# CC1350F128 register map
File version: 1.0
CPU: CM3 1.0, other endian, MPU, FPU, 3 interrupt priority bits
Registers are 32-bit, read-write, reset 0x0 unless marked. A register's access mark holds for its fields unless they carry their own. Offsets are from the block's base; [hi:lo] are bit positions; {n}, {i} and the like mark numbered series; 'fields as' and 'values as' point back to an identical list.

## PRCM — Power, Reset and Clock Management
Base 0x40082000
0x00 INFRCLKDIVR — Infrastructure Clock Division Factor For Run Mode
  [1:0] RATIO — [1:0] Division rate for clocks driving modules in the MCU_AON domain when system CPU is in run mode. Division ratio affects both infrastructure clock and perbusull clock.
    3=DIV32 (Divide by 32); 2=DIV8 (Divide by 8); 1=DIV2 (Divide by 2); 0=DIV1 (Divide by 1)
0x04 INFRCLKDIVS — Infrastructure Clock Division Factor For Sleep Mode
  [1:0] RATIO — [1:0] Division rate for clocks driving modules in the MCU_AON domain when system CPU is in sleep mode. Division ratio affects both infrastructure clock and perbusull clock.
    values as INFRCLKDIVR.RATIO
0x08 INFRCLKDIVDS — Infrastructure Clock Division Factor For DeepSleep Mode
  [1:0] RATIO — [1:0] Division rate for clocks driving modules in the MCU_AON domain when system CPU is in seepsleep mode. Division ratio affects both infrastructure clock and perbusull clock.
    values as INFRCLKDIVR.RATIO
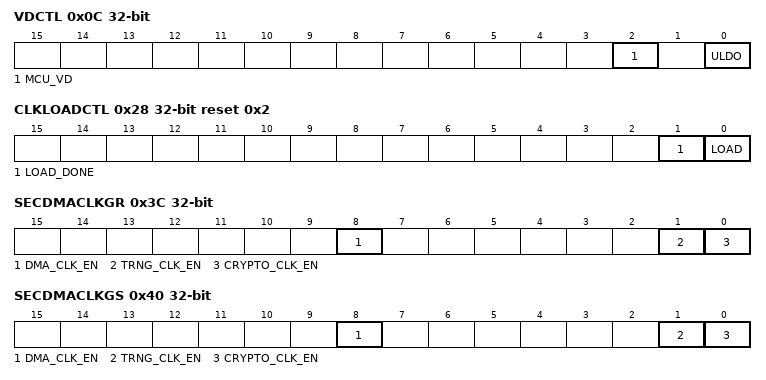
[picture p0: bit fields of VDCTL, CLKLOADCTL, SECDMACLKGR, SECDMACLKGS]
0x0C VDCTL — MCU Voltage Domain Control
  [2] MCU_VD — [2:2] Request WUC to power down the MCU voltage domain 0: No request 1: Assert request when possible. An asserted power down request will result in a boot of the MCU system when powered up again. The bit will have no effect before the following requirements are met: 1. PDCTL1.CPU_ON = 0 2. PDCTL1.VIMS_MODE = 0 3. SECDMACLKGDS.DMA_CLK_EN = 0 (Note: Setting must be loaded with CLKLOADCTL.LOAD) 4. SECDMACLKGDS.CRYPTO_CLK_EN = 0 (Note: Setting must be loaded with CLKLOADCTL.LOAD) 5. RFC do no request access to BUS 6. System CPU in deepsleep
  [0] ULDO — [0:0] Request WUC to switch to uLDO. 0: No request 1: Assert request when possible The bit will have no effect before the following requirements are met: 1. PDCTL1.CPU_ON = 0 2. PDCTL1.VIMS_MODE = 0 3. SECDMACLKGDS.DMA_CLK_EN = 0 (Note: Setting must be loaded with CLKLOADCTL.LOAD) 4. SECDMACLKGDS.CRYPTO_CLK_EN = 0 (Note: Setting must be loaded with CLKLOADCTL.LOAD) 5. RFC do no request access to BUS 6. System CPU in deepsleep
0x28 CLKLOADCTL reset 0x2 — Load PRCM Settings To CLKCTRL Power Domain
  [1] LOAD_DONE ro — [1:1] Status of LOAD. Will be cleared to 0 when any of the registers requiring a LOAD is written to, and be set to 1 when a LOAD is done. Note that writing no change to a register will result in the LOAD_DONE being cleared. 0 : One or more registers have been write accessed after last LOAD 1 : No registers are write accessed after last LOAD
  [0] LOAD wo — [0:0] 0: No action 1: Load settings to CLKCTRL. Bit is HW cleared. Multiple changes to settings may be done before LOAD is written once so all changes takes place at the same time. LOAD can also be done after single setting updates. Registers that needs to be followed by LOAD before settings being applied are: - RFCCLKG - VIMSCLKG - SECDMACLKGR - SECDMACLKGS - SECDMACLKGDS - GPIOCLKGR - GPIOCLKGS - GPIOCLKGDS - GPTCLKGR - GPTCLKGS - GPTCLKGDS - GPTCLKDIV - I2CCLKGR - I2CCLKGS - I2CCLKGDS - SSICLKGR - SSICLKGS - SSICLKGDS - UARTCLKGR - UARTCLKGS - UARTCLKGDS - I2SCLKGR - I2SCLKGS - I2SCLKGDS - I2SBCLKSEL - I2SCLKCTL - I2SMCLKDIV - I2SBCLKDIV - I2SWCLKDIV
0x2C RFCCLKG reset 0x1 — RFC Clock Gate
  [0] CLK_EN — [0:0] 0: Disable clock 1: Enable clock if RFC power domain is on For changes to take effect, CLKLOADCTL.LOAD needs to be written
0x30 VIMSCLKG reset 0x3 — VIMS Clock Gate
  [1:0] CLK_EN — [1:0] 00: Disable clock 01: Disable clock when system CPU is in DeepSleep 11: Enable clock For changes to take effect, CLKLOADCTL.LOAD needs to be written
0x3C SECDMACLKGR — TRNG, CRYPTO And UDMA Clock Gate For Run Mode
  [8] DMA_CLK_EN — [8:8] 0: Disable clock 1: Enable clock For changes to take effect, CLKLOADCTL.LOAD needs to be written
  [1] TRNG_CLK_EN — [1:1] 0: Disable clock 1: Enable clock For changes to take effect, CLKLOADCTL.LOAD needs to be written
  [0] CRYPTO_CLK_EN — [0:0] 0: Disable clock 1: Enable clock For changes to take effect, CLKLOADCTL.LOAD needs to be written
0x40 SECDMACLKGS — TRNG, CRYPTO And UDMA Clock Gate For Sleep Mode
  fields as SECDMACLKGR
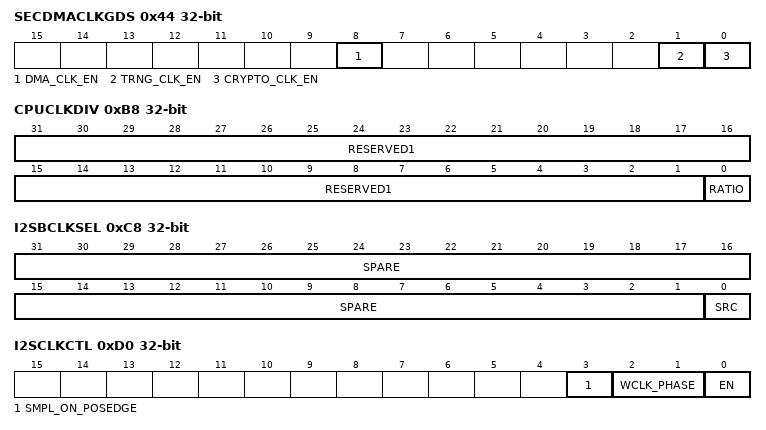
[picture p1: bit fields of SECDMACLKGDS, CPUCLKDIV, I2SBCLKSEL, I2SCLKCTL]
0x44 SECDMACLKGDS — TRNG, CRYPTO And UDMA Clock Gate For Deep Sleep Mode
  fields as SECDMACLKGR
0x48 GPIOCLKGR — GPIO Clock Gate For Run Mode
  [0] CLK_EN — [0:0] 0: Disable clock 1: Enable clock For changes to take effect, CLKLOADCTL.LOAD needs to be written
0x4C GPIOCLKGS — GPIO Clock Gate For Sleep Mode
  fields as GPIOCLKGR
0x50 GPIOCLKGDS — GPIO Clock Gate For Deep Sleep Mode
  fields as GPIOCLKGR
0x54 GPTCLKGR — GPT Clock Gate For Run Mode
  [3:0] CLK_EN — [3:0] Each bit below has the following meaning: 0: Disable clock 1: Enable clock ENUMs can be combined For changes to take effect, CLKLOADCTL.LOAD needs to be written
    8=GPT3 (Enable clock for GPT3); 4=GPT2 (Enable clock for GPT2); 2=GPT1 (Enable clock for GPT1); 1=GPT0 (Enable clock for GPT0)
0x58 GPTCLKGS — GPT Clock Gate For Sleep Mode
  fields as GPTCLKGR
0x5C GPTCLKGDS — GPT Clock Gate For Deep Sleep Mode
  fields as GPTCLKGR
0x60 I2CCLKGR — I2C Clock Gate For Run Mode
  fields as GPIOCLKGR
0x64 I2CCLKGS — I2C Clock Gate For Sleep Mode
  fields as GPIOCLKGR
0x68 I2CCLKGDS — I2C Clock Gate For Deep Sleep Mode
  fields as GPIOCLKGR
0x6C UARTCLKGR — UART Clock Gate For Run Mode
  fields as GPIOCLKGR
0x70 UARTCLKGS — UART Clock Gate For Sleep Mode
  fields as GPIOCLKGR
0x74 UARTCLKGDS — UART Clock Gate For Deep Sleep Mode
  fields as GPIOCLKGR
0x78 SSICLKGR — SSI Clock Gate For Run Mode
  [1:0] CLK_EN — [1:0] 0: Disable clock 1: Enable clock For changes to take effect, CLKLOADCTL.LOAD needs to be written
    2=SSI1 (Enable clock for SSI1); 1=SSI0 (Enable clock for SSI0)
0x7C SSICLKGS — SSI Clock Gate For Sleep Mode
  fields as SSICLKGR
0x80 SSICLKGDS — SSI Clock Gate For Deep Sleep Mode
  fields as SSICLKGR
0x84 I2SCLKGR — I2S Clock Gate For Run Mode
  fields as GPIOCLKGR
0x88 I2SCLKGS — I2S Clock Gate For Sleep Mode
  fields as GPIOCLKGR
0x8C I2SCLKGDS — I2S Clock Gate For Deep Sleep Mode
  fields as GPIOCLKGR
0xB8 CPUCLKDIV — Internal. Only to be used through TI provided API.
  [31:1] RESERVED1 ro — [31:1] Internal. Only to be used through TI provided API.
  [0] RATIO — [0:0] Internal. Only to be used through TI provided API.
    1=DIV2 (Internal. Only to be used through TI provided API.); 0=DIV1 (Internal. Only to be used through TI provided API.)
0xC0 PERBUSDMACLKDIV — Internal. Only to be used through TI provided API.
  [31:0] SPARE — [31:0] Internal. Only to be used through TI provided API.
0xC8 I2SBCLKSEL — I2S Clock Control
  [31:1] SPARE — [31:1] Software should not rely on the value of a reserved. Writing any other value than the reset value may result in undefined behavior.
  [0] SRC — [0:0] BCLK source selector 0: Use external BCLK 1: Use internally generated clock For changes to take effect, CLKLOADCTL.LOAD needs to be written
0xCC GPTCLKDIV — GPT Scalar
  [3:0] RATIO — [3:0] Scalar used for GPTs. The division rate will be constant and ungated for Run / Sleep / DeepSleep mode. For changes to take effect, CLKLOADCTL.LOAD needs to be written Other values are not supported.
    8=DIV256 (Divide by 256); 7=DIV128 (Divide by 128); 6=DIV64 (Divide by 64); 5=DIV32 (Divide by 32); 4=DIV16 (Divide by 16); 3=DIV8 (Divide by 8); 2=DIV4 (Divide by 4); 1=DIV2 (Divide by 2); 0=DIV1 (Divide by 1)
0xD0 I2SCLKCTL — I2S Clock Control
  [3] SMPL_ON_POSEDGE — [3:3] On the I2S serial interface, data and WCLK is sampled and clocked out on opposite edges of BCLK. 0 - data and WCLK are sampled on the negative edge and clocked out on the positive edge. 1 - data and WCLK are sampled on the positive edge and clocked out on the negative edge. For changes to take effect, CLKLOADCTL.LOAD needs to be written
  [2:1] WCLK_PHASE — [2:1] Decides how the WCLK division ratio is calculated and used to generate different duty cycles (See I2SWCLKDIV.WDIV). 0: Single phase 1: Dual phase 2: User Defined 3: Reserved/Undefined For changes to take effect, CLKLOADCTL.LOAD needs to be written
  [0] EN — [0:0] 0: MCLK, BCLK and WCLK will be static low 1: Enables the generation of MCLK, BCLK and WCLK For changes to take effect, CLKLOADCTL.LOAD needs to be written
0xD4 I2SMCLKDIV — MCLK Division Ratio
  [9:0] MDIV — [9:0] An unsigned factor of the division ratio used to generate MCLK [2-1024]: MCLK = MCUCLK/MDIV[Hz] MCUCLK is 48MHz in normal mode. For powerdown mode the frequency is defined by AON_WUC:MCUCLK.PWR_DWN_SRC A value of 0 is interpreted as 1024. A value of 1 is invalid. If MDIV is odd the low phase of the clock is one MCUCLK period longer than the high phase. For changes to take effect, CLKLOADCTL.LOAD needs to be written
0xD8 I2SBCLKDIV — BCLK Division Ratio
  [9:0] BDIV — [9:0] An unsigned factor of the division ratio used to generate I2S BCLK [2-1024]: BCLK = MCUCLK/BDIV[Hz] MCUCLK is 48MHz in normal mode. For powerdown mode the frequency is defined by AON_WUC:MCUCLK.PWR_DWN_SRC A value of 0 is interpreted as 1024. A value of 1 is invalid. If BDIV is odd and I2SCLKCTL.SMPL_ON_POSEDGE = 0, the low phase of the clock is one MCUCLK period longer than the high phase. If BDIV is odd and I2SCLKCTL.SMPL_ON_POSEDGE = 1 , the high phase of the clock is one MCUCLK period longer than the low phase. For changes to take effect, CLKLOADCTL.LOAD needs to be written
0xDC I2SWCLKDIV — WCLK Division Ratio
  [15:0] WDIV — [15:0] If I2SCLKCTL.WCLK_PHASE = 0, Single phase. WCLK is high one BCLK period and low WDIV[9:0] (unsigned, [1-1023]) BCLK periods. WCLK = MCUCLK / BDIV*(WDIV[9:0] + 1) [Hz] MCUCLK is 48MHz in normal mode. For powerdown mode the frequency is defined by AON_WUC:MCUCLK.PWR_DWN_SRC If I2SCLKCTL.WCLK_PHASE = 1, Dual phase. Each phase on WCLK (50% duty cycle) is WDIV[9:0] (unsigned, [1-1023]) BCLK periods. WCLK = MCUCLK / BDIV*(2*WDIV[9:0]) [Hz] If I2SCLKCTL.WCLK_PHASE = 2, User defined. WCLK is high WDIV[7:0] (unsigned, [1-255]) BCLK periods and low WDIV[15:8] (unsigned, [1-255]) BCLK periods. WCLK = MCUCLK / (BDIV*(WDIV[7:0] + WDIV[15:8]) [Hz] For changes to take effect, CLKLOADCTL.LOAD needs to be written
0x10C SWRESET — SW Initiated Resets
  [2] MCU wo — [2:2] Internal. Only to be used through TI provided API.
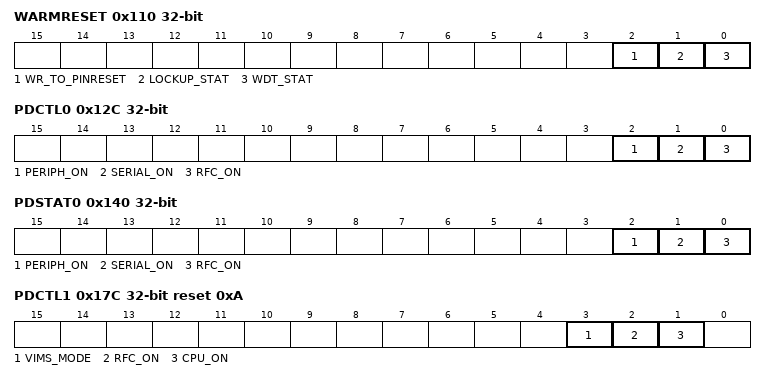
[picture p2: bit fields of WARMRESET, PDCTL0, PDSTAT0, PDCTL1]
0x110 WARMRESET — WARM Reset Control And Status
  [2] WR_TO_PINRESET — [2:2] 0: No action 1: A warm system reset event triggered by the below listed sources will result in an emulated pin reset. Warm reset sources included: ICEPick sysreset System CPU reset request, CPU_SCS:AIRCR.SYSRESETREQ System CPU Lockup WDT timeout An active ICEPick block system reset will gate all sources except ICEPick sysreset SW can read AON_SYSCTL:RESETCTL.RESET_SRC to find the source of the last reset resulting in a full power up sequence. WARMRESET in this register is set in the scenario that WR_TO_PINRESET=1 and one of the above listed sources is triggered.
  [1] LOCKUP_STAT ro — [1:1] 0: No registred event 1: A system CPU LOCKUP event has occured since last SW clear of the register. A read of this register clears both WDT_STAT and LOCKUP_STAT.
  [0] WDT_STAT ro — [0:0] 0: No registered event 1: A WDT event has occured since last SW clear of the register. A read of this register clears both WDT_STAT and LOCKUP_STAT.
0x12C PDCTL0 — Power Domain Control
  [2] PERIPH_ON — [2:2] PERIPH Power domain. 0: PERIPH power domain is powered down 1: PERIPH power domain is powered up
  [1] SERIAL_ON — [1:1] SERIAL Power domain. 0: SERIAL power domain is powered down 1: SERIAL power domain is powered up
  [0] RFC_ON — [0:0] 0: RFC power domain powered off if also PDCTL1.RFC_ON = 0 1: RFC power domain powered on
0x130 PDCTL0RFC — RFC Power Domain Control
  [0] ON — [0:0] Alias for PDCTL0.RFC_ON
0x134 PDCTL0SERIAL — SERIAL Power Domain Control
  [0] ON — [0:0] Alias for PDCTL0.SERIAL_ON
0x138 PDCTL0PERIPH — PERIPH Power Domain Control
  [0] ON — [0:0] Alias for PDCTL0.PERIPH_ON
0x140 PDSTAT0 — Power Domain Status
  [2] PERIPH_ON ro — [2:2] PERIPH Power domain. 0: Domain may be powered down 1: Domain powered up (guaranteed)
  [1] SERIAL_ON ro — [1:1] SERIAL Power domain. 0: Domain may be powered down 1: Domain powered up (guaranteed)
  [0] RFC_ON ro — [0:0] RFC Power domain 0: Domain may be powered down 1: Domain powered up (guaranteed)
0x144 PDSTAT0RFC — RFC Power Domain Status
  [0] ON ro — [0:0] Alias for PDSTAT0.RFC_ON
0x148 PDSTAT0SERIAL — SERIAL Power Domain Status
  [0] ON ro — [0:0] Alias for PDSTAT0.SERIAL_ON
0x14C PDSTAT0PERIPH — PERIPH Power Domain Status
  [0] ON ro — [0:0] Alias for PDSTAT0.PERIPH_ON
0x17C PDCTL1 reset 0xA — Power Domain Control
  [3] VIMS_MODE — [3:3] 0: VIMS power domain is only powered when CPU power domain is powered. 1: VIMS power domain is powered whenever the BUS power domain is powered.
  [2] RFC_ON — [2:2] 0: RFC power domain powered off if also PDCTL0.RFC_ON = 0 1: RFC power domain powered on Bit shall be used by RFC in autonomus mode but there is no HW restrictions fom system CPU to access the bit.
  [1] CPU_ON — [1:1] 0: Causes a power down of the CPU power domain when system CPU indicates it is idle. 1: Initiates power-on of the CPU power domain. This bit is automatically set by a WIC power-on event.
0x184 PDCTL1CPU reset 0x1 — CPU Power Domain Direct Control
  [0] ON — [0:0] This is an alias for PDCTL1.CPU_ON
0x188 PDCTL1RFC — RFC Power Domain Direct Control
  [0] ON — [0:0] This is an alias for PDCTL1.RFC_ON
0x18C PDCTL1VIMS reset 0x1 — VIMS Mode Direct Control
  [0] ON — [0:0] This is an alias for PDCTL1.VIMS_MODE
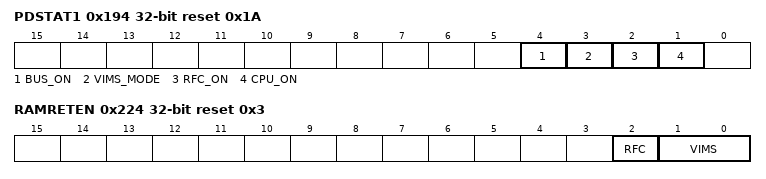
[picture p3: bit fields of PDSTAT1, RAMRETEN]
0x194 PDSTAT1 reset 0x1A — Power Manager Status
  [4] BUS_ON ro — [4:4] 0: BUS domain not accessible 1: BUS domain is currently accessible
  [3] VIMS_MODE ro — [3:3] 0: VIMS domain not accessible 1: VIMS domain is currently accessible
  [2] RFC_ON ro — [2:2] 0: RFC domain not accessible 1: RFC domain is currently accessible
  [1] CPU_ON ro — [1:1] 0: CPU and BUS domain not accessible 1: CPU and BUS domains are both currently accessible
0x198 PDSTAT1BUS reset 0x1 — BUS Power Domain Direct Read Status
  [0] ON ro — [0:0] This is an alias for PDSTAT1.BUS_ON
0x19C PDSTAT1RFC — RFC Power Domain Direct Read Status
  [0] ON ro — [0:0] This is an alias for PDSTAT1.RFC_ON
0x1A0 PDSTAT1CPU reset 0x1 — CPU Power Domain Direct Read Status
  [0] ON ro — [0:0] This is an alias for PDSTAT1.CPU_ON
0x1A4 PDSTAT1VIMS reset 0x1 — VIMS Mode Direct Read Status
  [0] ON ro — [0:0] This is an alias for PDSTAT1.VIMS_MODE
0x1CC RFCBITS — Control To RFC
  [31:0] READ — [31:0] Control bits for RFC. The RF core CPE processor will automatically check this register when it boots, and it can be used to immediately instruct CPE to perform some tasks at its start-up. The supported functionality is ROM-defined and may vary. See the technical reference manual for more details.
0x1D0 RFCMODESEL — Selected RFC Mode
  [2:0] CURR — [2:0] Selects the set of commands that the RFC will accept. Only modes permitted by RFCMODEHWOPT.AVAIL are writeable. See the technical reference manual for details.
    {v}=MODE{v} (Select Mode {v}) (v=0..7)
0x1D4 RFCMODEHWOPT — Allowed RFC Modes
  [7:0] AVAIL ro — [7:0] Permitted RFC modes. More than one mode can be permitted.
    128=MODE7 (Mode 7 permitted); 64=MODE6 (Mode 6 permitted); 32=MODE5 (Mode 5 permitted); 16=MODE4 (Mode 4 permitted); 8=MODE3 (Mode 3 permitted); 4=MODE2 (Mode 2 permitted); 2=MODE1 (Mode 1 permitted); 1=MODE0 (Mode 0 permitted)
0x1E0 PWRPROFSTAT reset 0x1 — Power Profiler Register
  [7:0] VALUE — [7:0] SW can use these bits to timestamp the application. These bits are also available through the testtap and can thus be used by the emulator to profile in real time.
0x224 RAMRETEN reset 0x3 — Memory Retention Control
  [2] RFC — [2:2] 0: Retention for RFC SRAM disabled 1: Retention for RFC SRAM enabled Memories controlled: CPERAM MCERAM RFERAM
  [1:0] VIMS — [1:0] 0: Memory retention disabled 1: Memory retention enabled Bit 0: VIMS_TRAM Bit 1: VIMS_CRAM Legal modes depend on settings in VIMS:CTL.MODE 00: VIMS:CTL.MODE must be OFF before DEEPSLEEP is asserted - must be set to CACHE or SPLIT mode after waking up again 01: VIMS:CTL.MODE must be GPRAM before DEEPSLEEP is asserted. Must remain in GPRAM mode after wake up, alternatively select OFF mode first and then CACHE or SPILT mode. 10: Illegal mode 11: No restrictions
